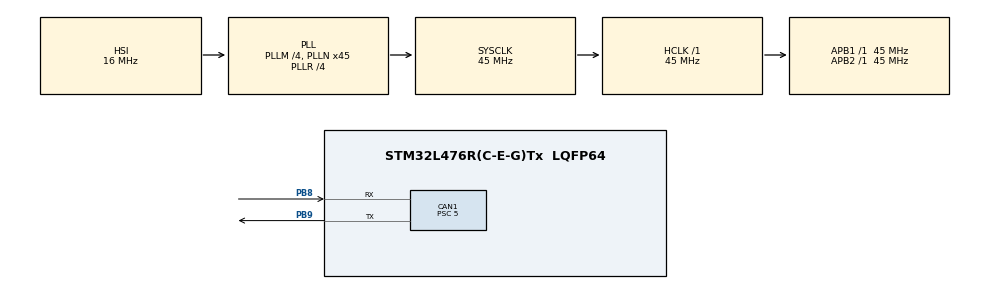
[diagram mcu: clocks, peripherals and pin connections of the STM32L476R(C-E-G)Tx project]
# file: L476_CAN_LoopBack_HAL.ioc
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CAN1.BS1=CAN_BS1_15TQ
CAN1.BS2=CAN_BS2_2TQ
CAN1.CalculateBaudRate=500000
CAN1.CalculateTimeBit=2000
CAN1.CalculateTimeQuantum=111.11111111111111
CAN1.Mode=CAN_MODE_LOOPBACK
CAN1.Prescaler=5
Mcu.Family=STM32L4
Mcu.Name=STM32L476R(C-E-G)Tx
Mcu.Package=LQFP64
NVIC.PriorityGroup=NVIC_PRIORITYGROUP_4
PB8.Mode=CAN_Activate
PB8.Signal=CAN1_RX
PB9.Mode=CAN_Activate
PB9.Signal=CAN1_TX
PC14-OSC32_IN\ (PC14).Mode=LSE-External-Oscillator
PC14-OSC32_IN\ (PC14).Signal=RCC_OSC32_IN
PC15-OSC32_OUT\ (PC15).Mode=LSE-External-Oscillator
PC15-OSC32_OUT\ (PC15).Signal=RCC_OSC32_OUT
ProjectManager.HeapSize=0x200
ProjectManager.StackSize=0x400
ProjectManager.TargetToolchain=MDK-ARM V5.32
RCC.ADCFreq_Value=16000000
RCC.AHBFreq_Value=45000000
RCC.APB1Freq_Value=45000000
RCC.APB1TimFreq_Value=45000000
RCC.APB2Freq_Value=45000000
RCC.APB2TimFreq_Value=45000000
RCC.CortexFreq_Value=45000000
RCC.HCLKFreq_Value=45000000
RCC.HSE_VALUE=8000000
RCC.HSI_VALUE=16000000
RCC.MSI_VALUE=4000000
RCC.PLLM=4
RCC.PLLN=45
RCC.PLLR=RCC_PLLR_DIV4
RCC.PLLSourceVirtual=RCC_PLLSOURCE_HSI
RCC.PREFETCH_ENABLE=1
RCC.SYSCLKFreq_VALUE=45000000
RCC.SYSCLKSource=RCC_SYSCLKSOURCE_PLLCLK
RCC.USBFreq_Value=16000000
RCC.VCOOutputFreq_Value=180000000
board=NUCLEO-L476RG

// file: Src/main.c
/* USER CODE BEGIN Header */
/**
  ******************************************************************************
  * @file           : main.c
  * @brief          : Main program body
  ******************************************************************************
  * @attention
  *
  * Copyright (c) 2024 STMicroelectronics.
  * All rights reserved.
  *
  * This software is licensed under terms that can be found in the LICENSE file
  * in the root directory of this software component.
  * If no LICENSE file comes with this software, it is provided AS-IS.
  *
  ******************************************************************************
  */
/* USER CODE END Header */
#include "main.h"

CAN_HandleTypeDef hcan1;

void SystemClock_Config(void);
static void MX_GPIO_Init(void);
static void MX_CAN1_Init(void);

/* USER CODE BEGIN 0 */
CAN_TxHeaderTypeDef   TxHeader;
CAN_RxHeaderTypeDef   RxHeader;
uint8_t               TxData[8];
uint8_t               RxData[8];
uint32_t              TxMailbox;
/* USER CODE END 0 */

int main(void)
{

  /* MCU Configuration--------------------------------------------------------*/

  /* Reset of all peripherals, Initializes the Flash interface and the Systick. */
  HAL_Init();

  /* Configure the system clock */
  SystemClock_Config();

  /* Initialize all configured peripherals */
  MX_GPIO_Init();
  MX_CAN1_Init();
  /* USER CODE BEGIN 2 */
	if (HAL_CAN_Start(&hcan1) != HAL_OK)
  {
    /* Start Error */
    Error_Handler();
  }

	TxHeader.StdId = 0x11;
  TxHeader.RTR = CAN_RTR_DATA;
  TxHeader.IDE = CAN_ID_STD;
  TxHeader.DLC = 8;
  TxHeader.TransmitGlobalTime = DISABLE;
  TxData[0] = 0xAA;
	TxData[1] = 0xBB;
	TxData[2] = 0xCC;
	TxData[3] = 0xDD;
	TxData[4] = 0x11;
	TxData[5] = 0x22;
	TxData[6] = 0x33;
	TxData[7] = 0x44;

	if(HAL_CAN_AddTxMessage(&hcan1, &TxHeader, TxData, &TxMailbox) != HAL_OK)
  {
    /* Transmission request Error */
    Error_Handler();
  }
	while(HAL_CAN_GetTxMailboxesFreeLevel(&hcan1) != 3) {}

	if(HAL_CAN_GetRxFifoFillLevel(&hcan1, CAN_RX_FIFO0) != 1)
  {
    /* Reception Missing */
    Error_Handler();
  }

	if(HAL_CAN_GetRxMessage(&hcan1, CAN_RX_FIFO0, &RxHeader, RxData) != HAL_OK)
  {
    /* Reception Error */
    Error_Handler();
  }

	if((RxHeader.StdId != 0x11)                     ||
     (RxHeader.RTR != CAN_RTR_DATA)               ||
     (RxHeader.IDE != CAN_ID_STD)                 ||
     (RxHeader.DLC != 0)                          ||
     ((RxData[0]<<8 | RxData[1]) != 0xCAFE))
  {
    /* Rx message Error */
    Error_Handler();
  }

  /* USER CODE END 2 */

  /* Infinite loop */
  while (1)
  {

  }
}

void SystemClock_Config(void)
{
  RCC_OscInitTypeDef RCC_OscInitStruct = {0};
  RCC_ClkInitTypeDef RCC_ClkInitStruct = {0};

  /** Configure the main internal regulator output voltage
  */
  if (HAL_PWREx_ControlVoltageScaling(PWR_REGULATOR_VOLTAGE_SCALE1) != HAL_OK)
  {
    Error_Handler();
  }

  /** Initializes the RCC Oscillators according to the specified parameters
  * in the RCC_OscInitTypeDef structure.
  */
  RCC_OscInitStruct.OscillatorType = RCC_OSCILLATORTYPE_HSI;
  RCC_OscInitStruct.HSIState = RCC_HSI_ON;
  RCC_OscInitStruct.HSICalibrationValue = RCC_HSICALIBRATION_DEFAULT;
  RCC_OscInitStruct.PLL.PLLState = RCC_PLL_ON;
  RCC_OscInitStruct.PLL.PLLSource = RCC_PLLSOURCE_HSI;
  RCC_OscInitStruct.PLL.PLLM = 4;
  RCC_OscInitStruct.PLL.PLLN = 45;
  RCC_OscInitStruct.PLL.PLLP = RCC_PLLP_DIV7;
  RCC_OscInitStruct.PLL.PLLQ = RCC_PLLQ_DIV2;
  RCC_OscInitStruct.PLL.PLLR = RCC_PLLR_DIV4;
  if (HAL_RCC_OscConfig(&RCC_OscInitStruct) != HAL_OK)
  {
    Error_Handler();
  }

  /** Initializes the CPU, AHB and APB buses clocks
  */
  RCC_ClkInitStruct.ClockType = RCC_CLOCKTYPE_HCLK|RCC_CLOCKTYPE_SYSCLK
                              |RCC_CLOCKTYPE_PCLK1|RCC_CLOCKTYPE_PCLK2;
  RCC_ClkInitStruct.SYSCLKSource = RCC_SYSCLKSOURCE_PLLCLK;
  RCC_ClkInitStruct.AHBCLKDivider = RCC_SYSCLK_DIV1;
  RCC_ClkInitStruct.APB1CLKDivider = RCC_HCLK_DIV1;
  RCC_ClkInitStruct.APB2CLKDivider = RCC_HCLK_DIV1;

  if (HAL_RCC_ClockConfig(&RCC_ClkInitStruct, FLASH_LATENCY_2) != HAL_OK)
  {
    Error_Handler();
  }
}

static void MX_CAN1_Init(void)
{

  hcan1.Instance = CAN1;
  hcan1.Init.Prescaler = 5;
  hcan1.Init.Mode = CAN_MODE_LOOPBACK;
  hcan1.Init.SyncJumpWidth = CAN_SJW_1TQ;
  hcan1.Init.TimeSeg1 = CAN_BS1_15TQ;
  hcan1.Init.TimeSeg2 = CAN_BS2_2TQ;
  hcan1.Init.TimeTriggeredMode = DISABLE;
  hcan1.Init.AutoBusOff = DISABLE;
  hcan1.Init.AutoWakeUp = DISABLE;
  hcan1.Init.AutoRetransmission = DISABLE;
  hcan1.Init.ReceiveFifoLocked = DISABLE;
  hcan1.Init.TransmitFifoPriority = DISABLE;
  if (HAL_CAN_Init(&hcan1) != HAL_OK)
  {
    Error_Handler();
  }
  /* USER CODE BEGIN CAN1_Init 2 */
	CAN_FilterTypeDef  sFilterConfig;
	sFilterConfig.FilterBank = 0;
  sFilterConfig.FilterMode = CAN_FILTERMODE_IDMASK;
  sFilterConfig.FilterScale = CAN_FILTERSCALE_32BIT;
  sFilterConfig.FilterIdHigh = 0x0000;
  sFilterConfig.FilterIdLow = 0x0000;
  sFilterConfig.FilterMaskIdHigh = 0x0000;
  sFilterConfig.FilterMaskIdLow = 0x0000;
  sFilterConfig.FilterFIFOAssignment = CAN_RX_FIFO0;
  sFilterConfig.FilterActivation = ENABLE;
  sFilterConfig.SlaveStartFilterBank = 14;

  if(HAL_CAN_ConfigFilter(&hcan1, &sFilterConfig) != HAL_OK)
  {
    /* Filter configuration Error */
    Error_Handler();
  }
  /* USER CODE END CAN1_Init 2 */

}

static void MX_GPIO_Init(void)
{

  /* GPIO Ports Clock Enable */
  __HAL_RCC_GPIOC_CLK_ENABLE();
  __HAL_RCC_GPIOB_CLK_ENABLE();

}

void Error_Handler(void)
{
  __disable_irq();
  while (1)
  {
  }
}
